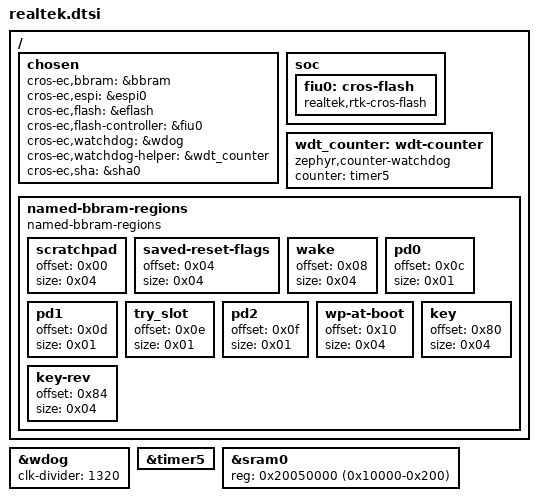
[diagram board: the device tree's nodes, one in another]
/* Copyright 2025 The ChromiumOS Authors
 * Use of this source code is governed by a BSD-style license that can be
 * found in the LICENSE file.
 */

#include <cros/binman.dtsi>

/ {
	chosen {
		cros-ec,bbram = &bbram;
		cros-ec,espi = &espi0;
		cros-ec,flash = &eflash;
		cros-ec,flash-controller = &fiu0;
		cros-ec,watchdog = &wdog;
		cros-ec,watchdog-helper = &wdt_counter;
		cros-ec,sha= &sha0;
    };
	soc {
		fiu0: cros-flash {
			compatible = "realtek,rtk-cros-flash";
		};
	};

	wdt_counter: wdt-counter {
		compatible = "zephyr,counter-watchdog";
		status = "okay";
		counter = <&timer5>;
	};

	named-bbram-regions {
		compatible = "named-bbram-regions";

		scratchpad {
			offset = <0x00>;
			size = <0x04>;
		};
		saved-reset-flags {
			offset = <0x04>;
			size = <0x04>;
		};
		wake {
			offset = <0x08>;
			size = <0x04>;
		};
		pd0 {
			offset = <0x0c>;
			size = <0x01>;
		};
		pd1 {
			offset = <0x0d>;
			size = <0x01>;
		};
		try_slot {
			offset = <0x0e>;
			size = <0x01>;
		};
		pd2 {
			offset = <0x0f>;
			size = <0x01>;
		};
		wp-at-boot {
			offset = <0x10>;
			size = <0x04>;
		};
		key {
			offset = <0x80>;
			size = <0x04>;
		};
		key-rev {
			offset = <0x84>;
			size = <0x04>;
		};
	};
};

&wdog {
	status = "okay";
	clk-divider = <1320>;
};

&timer5 {
        status = "okay";
};

/* TODO: b/418727861 - remove once the ROM log is reserved upstream */
&sram0 {
	reg = < 0x20050000 (0x10000-0x200) >;
};
